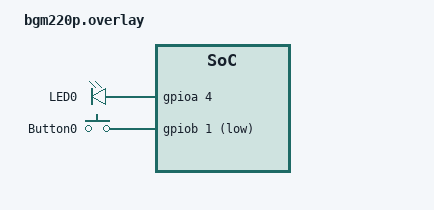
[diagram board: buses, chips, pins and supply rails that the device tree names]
/ {
	leds {
		compatible = "gpio-leds";
		led0: led_0 {
			gpios = <&gpioa 4 GPIO_ACTIVE_HIGH>;
			label = "LED0";
		};
	};

	buttons {
		compatible = "gpio-keys";
		button0: button_0 {
			gpios = <&gpiob 1 GPIO_ACTIVE_LOW>;
			label = "Button0";
		};
	};
};

